# NUC029DE_v1 register map
File version: 1.0
Registers are 32-bit, read-write, reset 0x0 unless marked. A register's access mark holds for its fields unless they carry their own. Offsets are from the block's base; [hi:lo] are bit positions; {n}, {i} and the like mark numbered series; 'fields as' and 'values as' point back to an identical list.

## UART1 — UART Register Map
Base 0x40150000
0x00 UA_RBR ro reset not defined — UART Receive Buffer Register
  [7:0] RBR — Receive Buffer Register (Read Only). By reading this register, the UART will return the 8-bit data received from RX pin (LSB first).
0x00 UA_THR wo reset not defined (alternate view of UA_RBR) — UART Transmit Holding Register
  [7:0] THR — Transmit Holding Register. By writing one byte to this register, the data byte will be stored in transmitter FIFO. The UART Controller will send out the data stored in transmitter FIFO top location through the TX pin.
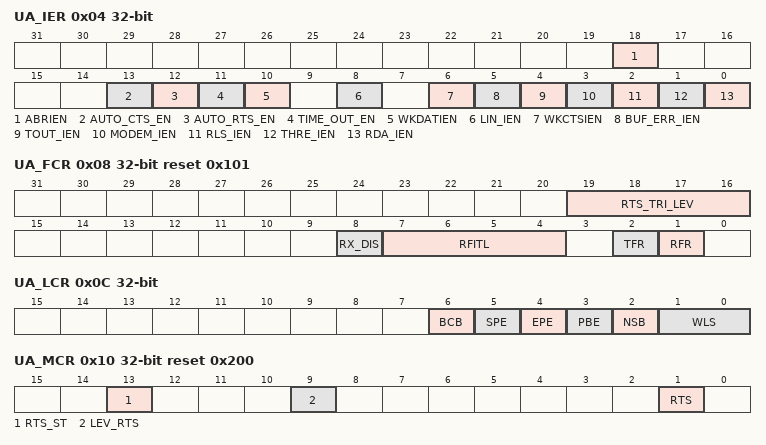
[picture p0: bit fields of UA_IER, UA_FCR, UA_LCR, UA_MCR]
0x04 UA_IER — UART Interrupt Enable Register
  [18] ABRIEN — Auto-Baud Rate Interrupt Enable Control
    0=Auto-baud rate interrupt Disabled; 1=Auto-baud rate interrupt Enabled
  [13] AUTO_CTS_EN — CTS Auto Flow Control Enable Coontrol (Available In UART0/UART1 Channel). When CTS auto-flow is enabled, the UART will send data to external device when CTS input assert (UART will not send data to device until CTS is asserted).
    0=CTS auto flow control Disabled; 1=CTS auto flow control Enabled
  [12] AUTO_RTS_EN — RTS Auto Flow Control Enable Coontrol ( Available In UART0/UART1 Channel). When RTS auto-flow is enabled, if the number of bytes in the RX FIFO equals the RTS_TRI_LEV (UA_FCR [19:16]), the UART will de-assert RTS signal.
    0=RTS auto flow control Disabled; 1=RTS auto flow control Enabled
  [11] TIME_OUT_EN — Time-Out Counter Enable Coontrol
    0=Time-out counter Disabled; 1=Time-out counter Enabled
  [10] WKDATIEN — Incoming Data Wake-Up Interrupt Enable Control. Note: Hardware will clear this bit when the incoming data wake-up operation finishes and "system clock" work stable.
    0=Incoming data wake-up system function Disabled; 1=Incoming data wake-up system function Enabled, when the system is in Power-down mode, incoming data will wake-up system from Power-down mode
  [8] LIN_IEN — LIN Bus Interrupt Enable Coontrol. Note: This field is used for LIN function mode.
    0=Lin bus interrupt Disabled; 1=Lin bus interrupt Enabled
  [6] WKCTSIEN — NCTS Wake-Up Interrupt Enable Control
    0=nCTS wake-up system function Disabled; 1=Wake-up system function Enabled, when the system is in Power-down mode, an external nCTS change will wake-up system from Power-down mode
  [5] BUF_ERR_IEN — Buffer Error Interrupt Enable Coontrol
    0=BUF_ERR_INT Masked off; 1=BUF_ERR_INT Enabled
  [4] TOUT_IEN — RX Time-Out Interrupt Enable Coontrol
    0=TOUT_INT Masked off; 1=TOUT_INT Enabled
  [3] MODEM_IEN — Modem Status Interrupt Enable Coontrol (Available In UART0/UART1 Channel)
    0=MODEM_INT Masked off; 1=MODEM_INT Enabled
  [2] RLS_IEN — Receive Line Status Interrupt Enable Coontrol
    0=RLS_INT Masked off; 1=RLS_INT Enabled
  [1] THRE_IEN — Transmit Holding Register Empty Interrupt Enable Coontrol
    0=THRE_INT Masked off; 1=THRE_INT Enabled
  [0] RDA_IEN — Receive Data Available Interrupt Enable Coontrol
    0=RDA_INT Masked off; 1=RDA_INT Enabled
0x08 UA_FCR reset 0x101 — UART FIFO Control Register
  [19:16] RTS_TRI_LEV — RTS Trigger Level For Auto-Flow Control Use (Available In UART0/UART1 Channel). Note: This field is used for RTS auto-flow control.
    0=RTS Trigger Level is 1 byte; 1=RTS Trigger Level is 4 bytes; 2=RTS Trigger Level is 8 bytes; 3=RTS Trigger Level is 14 bytes
  [8] RX_DIS — Receiver Disable Bit. The receiver is disabled or not (set 1 to disable receiver). Note: This field is used for RS-485 Normal Multi-drop mode. It should be programmed before RS-485_NMM (UA_ALT_CSR[8]) is programmed.
    0=Receiver Enabled; 1=Receiver Disabled
  [7:4] RFITL — RX FIFO Interrupt (INT_RDA) Trigger Level (Available In UART0/UART1/UART2 Channel). When the number of bytes in the receive FIFO equals the RFITL, the RDA_IF will be set (if UA_IER [RDA_IEN] enabled, and an interrupt will be generated).
    0=RX FIFO Interrupt Trigger Level is 1 byte. RX Buffer Interrupt Trigger Level is 1 byte; 1=RX FIFO Interrupt Trigger Level is 4 bytes; 2=RX FIFO Interrupt Trigger Level is 8 bytes; 3=RX FIFO Interrupt Trigger Level is 14 bytes
  [2] TFR — TX Field Software Reset. When TFR is set, all the byte in the transmit FIFO/ transmit buffer and TX internal state machine are cleared. Note: This bit will automatically clear at least 3 UART peripherial clock cycles.
    0=No effect; 1=Reset the TX internal state machine and pointers
  [1] RFR — RX Field Software Reset. When RFR is set, all the byte in the receiver FIFO /receive buffer and RX internal state machine are cleared. Note: This bit will automatically clear at least 3 UART peripherial clock cycles.
    0=No effect; 1=Reset the RX internal state machine and pointers
0x0C UA_LCR — UART Line Control Register
  [6] BCB — Break Control Bit. When this bit is set to logic 1, the serial data output (TX) is forced to the Spacing State (logic 0). This bit acts only on TX and has no effect on the transmitter logic.
  [5] SPE — Stick Parity Enable Coontrol
    0=Stick parity Disabled; 1=If PBE (UA_LCR[3]) and EBE (UA_LCR[4]) are logic 1, the parity bit is transmitted and checked as logic 0. If PBE (UA_LCR[3]) is 1 and EBE (UA_LCR[4]) is 0 then the parity bit is transmitted and checked as 1
  [4] EPE — Even Parity Enable Coontrol. This bit has effect only when PBE (UA_LCR[3]) is set.
    0=Odd number of logic 1's is transmitted and checked in each word; 1=Even number of logic 1's is transmitted and checked in each word
  [3] PBE — Parity Bit Enable Coontrol
    0=No parity bit; 1=Parity bit is generated on each outgoing character and is checked on each incoming data
  [2] NSB — Number Of "STOP Bit"
    0=One " STOP bit" is generated in the transmitted data; 1=When select 5-bit word length, 1.5 "STOP bit" is generated in the transmitted data. When select 6-,7- and 8-bti word length, 2 "STOP bit" is generated in the transmitted data
  [1:0] WLS — Word Length Selection
    {v}=Word length is {v+5}-bit (v=0..3)
0x10 UA_MCR reset 0x200 — UART Modem Control Register
  [13] RTS_ST ro — RTS Pin State (Read Only) ( Available In UART0/UART1 Channel). This bit mirror from RTS pin output of voltage logic status.
    0=RTS pin output is low level voltage logic state; 1=RTS pin output is high level voltage logic state
  [9] LEV_RTS — RTS Pin Active Level ( Available In UART0/UART1 Channel). This bit defines the active level state of RTS pin output. Note1: Refer to Figure 692 and Figure 693 for UART function mode. Note2: Refer to Figure 6103 and Figure 6104 for RS-485 function mode.
    0=RTS pin output is high level active; 1=RTS pin output is low level active
  [1] RTS — RTS (Request-To-Send) Signal Control (Available In UART0/UART1 Channel). This bit is direct control internal RTS signal active or not, and then drive the RTS pin output with LEV_RTS bit configuration. Note1: This RTS signal control bit is not effective when RTS auto-flow control is enabled in UART function mode. Note2: This RTS signal control bit is not effective when RS-485 auto direction mode (AUD) is enabled in RS-485 function mode.
    0=RTS signal is active; 1=RTS signal is inactive
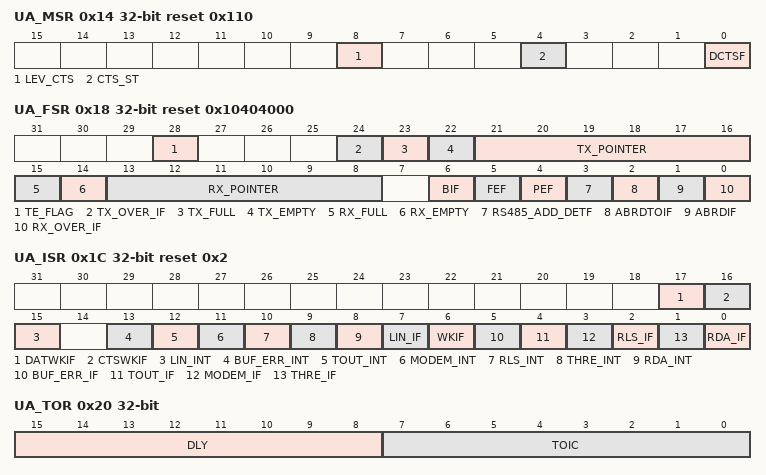
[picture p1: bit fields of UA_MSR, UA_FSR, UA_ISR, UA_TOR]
0x14 UA_MSR reset 0x110 — UART Modem Status Register
  [8] LEV_CTS — CTS Pin Active Level. This bit defines the active level state of CTS pin input. Note: Refer to Figure 691 for more information.
    0=CTS pin input is high level active; 1=CTS pin input is low level active
  [4] CTS_ST ro — CTS Pin Status (Read Only). This bit mirror from CTS pin input of voltage logic status. Note: This bit echoes when UART Controller peripheral clock is enabled, and CTS multi-function port is selected.
    0=CTS pin input is low level voltage logic state; 1=CTS pin input is high level voltage logic state
  [0] DCTSF ro — Detect CTS State Change Flag (Read Only). This bit is set whenever CTS input has change state, and it will generate Modem interrupt to CPU when MODEM_IEN (UA_IER [3]) is set to 1. Note: This bit is read only, but can be cleared by writing "1" to it.
    0=CTS input has not change state; 1=CTS input has change state
0x18 UA_FSR reset 0x10404000 — UART FIFO Status Register
  [28] TE_FLAG ro — Transmitter Empty Flag (Read Only). This bit is set by hardware when TX FIFO (UA_THR) is empty and the STOP bit of the last byte has been transmitted. (UART0/UART1/UART2). Note: This bit is cleared automatically when TX FIFO/TX Buffer is not empty or the last byte transmission has not completed.
    0=TX FIFO is not empty. TX Buffer is not empty; 1=TX FIFO is empty. TX Buffer is empty
  [24] TX_OVER_IF ro — TX Overflow Error Interrupt Flag (Read Only). If TX FIFO (UA_THR) is full, an additional write to UA_THR will cause this bit to logic 1. (UART0/UART1/UART2). Note: This bit is read only, but can be cleared by writing "1" to it.
    0=TX FIFO is not overflow. TX Buffer is not overflow; 1=TX FIFO is overflow. TX Buffer is overflow
  [23] TX_FULL ro — Transmitter FIFO Full (Read Only). This bit indicates TX FIFO is full or not. (UART0/UART1/UART2). This bit is set when the number of usage in TX Buffer is equal to 1 (UART3/UART4/UART5), otherwise is cleared by hardware.
    0=TX FIFO is not full. TX Buffer is not full; 1=TX FIFO is full. TX Buffer is full
  [22] TX_EMPTY ro — Transmitter FIFO Empty (Read Only). This bit indicates TX FIFO empty or not. (UART0/UART1/UART2). Note: When the last byte of TX Buffer has been transferred to Transmitter Shift Register, hardware sets this bit high. It will be cleared when writing data into THR (TX FIFO not empty).
    values as TE_FLAG
  [21:16] TX_POINTER ro — TX FIFO Pointer (Read Only). This field indicates the TX FIFO Buffer Pointer. When CPU writes one byte into UA_THR, then TX_POINTER increases one. When one byte of TX FIFO is transferred to Transmitter Shift Register, then TX_POINTER decreases one. The Maximum value shown in TX_POINTER is 15 (UART0/UART1/UART2). When the using level of TX FIFO Buffer is equal to 16, the TX_FULL bit is set to 1 and TX_POINTER will show 0. As one byte of TX FIFO is transferred to Transmitter Shift Register, the TX_FULL bit is cleared to 0 and TX_POINTER will show 15 (UART0/UART1/UART2). TX_POINTER is 0 (UART3/URT4/UART5). When TX Buffer is equal to 1, if one byte data is received, the TX_FULL bit is set to 1 and TX_POINTER will show 1. Once the TX Buffer is read, the TX_POINTER is 0.
  [15] RX_FULL ro — Receiver FIFO Full (Read Only). This bit initiates RX FIFO is full or not (UART0/UART1/UART2). Note: This bit is set when the number of usage in RX Buffer is equal to 1 (UART3/UART4/UART5), otherwise is cleared by hardware.
    0=RX FIFO is not full. RX buffer is not full; 1=RX FIFO is full. RX bufferis full
  [14] RX_EMPTY ro — Receiver FIFO Empty (Read Only). This bit initiate RX FIFO empty or not. (UART0/UART1/UART2). Note: When the last byte of RX Buffer has been read by CPU, hardware sets this bit high. It will be cleared when UART receives any new data.
    0=RX FIFO is not empty. RX Buffer is not empty; 1=RX FIFO is empty. RX Buffer is empty
  [13:8] RX_POINTER ro — RX FIFO Pointer (Read Only). This field indicates the RX FIFO Buffer Pointer. When UART receives one byte from external device, then RX_POINTER increases one. When one byte of RX FIFO is read by CPU, then RX_POINTER decreases one. The Maximum value shown in RX_POINTER is 15 (UART0/UART1/UART2). When the using level of RX FIFO Buffer equal to 16, the RX_FULL bit is set to 1 and RX_POINTER will show 0. As one byte of RX FIFO is read by CPU, the RX_FULL bit is cleared to 0 and RX_POINTER will show 15 (UART0/UART1/UART2). When RX Buffer is equal to 1, if one byte data is received, the RX_FULL bit is set to 1 and RX_POINTER will show 1. Once the RX Buffer is read, the RX_POINTER is 0.
  [6] BIF ro — Break Interrupt Flag (Read Only). This bit is set to logic 1 whenever the received data input(RX) is held in the "spacing state" (logic 0) for longer than a full word transmission time (that is, the total time of "start bit" + data bits + parity + stop bits) and is reset whenever the CPU writes 1 to this bit. Note: This bit is read only, but can be cleared by writing "1" to it.
    0=No Break interrupt is generated; 1=Break interrupt is generated
  [5] FEF ro — Framing Error Flag (Read Only). This bit is set to logic 1 whenever the received character does not have a valid "stop bit" (that is, the stop bit following the last data bit or parity bit is detected as logic 0), and is reset whenever the CPU writes 1 to this bit. Note: This bit is read only, but can be cleared by writing "1" to it.
    0=No framing error is generated; 1=Framing error is generated
  [4] PEF ro — Parity Error Flag (Read Only). This bit is set to logic 1 whenever the received character does not have a valid "parity bit", and is reset whenever the CPU writes 1 to this bit. Note: This bit is read only, but can be cleared by writing "1" to it.
    0=No parity error is generated; 1=Parity error is generated
  [3] RS485_ADD_DETF ro — RS-485 Address Byte Detection Flag (Read Only) (Available In UART0/UART1). Note1: This field is used for RS-485 function mode and RS485_ADD_EN (UA_ALT_CSR[15]) is set to 1 to enable Address detection mode. Note2: This bit is read only, but can be cleared by writing '1' to it.
    0=Receiver detects a data that is not an address bit (bit 9 ='1'); 1=Receiver detects a data that is an address bit (bit 9 ='1')
  [2] ABRDTOIF ro — Auto-Baud Rate Time-Out Interrupt (Read Only). Note1: This bit is set to logic "1" in Auto-baud Rate Detect mode and the baud rate counter is overflow. Note2: This bit is read only, but can be cleared by writing "1" to it.
    0=Auto-baud rate counter is underflow; 1=Auto-baud rate counter is overflow
  [1] ABRDIF ro — Auto-Baud Rate Detect Interrupt (Read Only). This bit is set to logic "1" when auto-baud rate detect function is finished. Note: This bit is read only, but can be cleared by writing "1" to it.
    0=Auto-baud rate detect function is not finished; 1=Auto-baud rate detect function is finished
  [0] RX_OVER_IF ro — RX Overflow Error IF (Read Only). This bit is set when RX FIFO overflow. If the number of bytes of received data is greater than RX_FIFO (UA_RBR) size, 16 bytes of UART0/UART1/UART2, this bit will be set. Note: This bit is read only, but can be cleared by writing "1" to it.
    0=RX FIFO is not overflow. RX Buffer is not overflow; 1=RX FIFO is overflow. RX Buffer is overflow
0x1C UA_ISR reset 0x2 — UART Interrupt Status Register
  [17] DATWKIF ro — Data Wake-Up Interrupt Flag (Read Only). This bit is set if chip wake-up from power-down state by data wake-up. Note1: If WKDATIEN (UA_IER[10]) is enabled, the wake-up interrupt is generated. Note2: This bit is read only, but can be cleared by writing '1' to it.
    0=Chip stays in power-down state; 1=Chip wake-up from power-down state by data wake-up
  [16] CTSWKIF ro — NCTS Wake-Up Interrupt Flag (Read Only). Note1: If WKCTSIEN (UA_IER[6])is enabled, the wake-up interrupt is generated. Note2: This bit is read only, but can be cleared by writing '1' to it.
    0=Chip stays in power-down state; 1=Chip wake-up from power-down state by nCTS wake-up
  [15] LIN_INT ro — LIN Bus Interrupt Indicator (Read Only). This bit is set if LIN_IEN (UA_IER[8]) and LIN _IF(UA_ISR[7]) are both set to 1.
    0=No LIN Bus interrupt is generated; 1=The LIN Bus interrupt is generated
  [13] BUF_ERR_INT ro — Buffer Error Interrupt Indicator (Read Only). This bit is set if BUF_ERR_IEN(UA_IER[5] and BUF_ERR_IF(UA_ISR[5]) are both set to 1.
    0=No buffer error interrupt is generated; 1=Buffer error interrupt is generated
  [12] TOUT_INT ro — Time-Out Interrupt Indicator (Read Only). This bit is set if TOUT_IEN(UA_IER[4]) and TOUT_IF(UA_ISR[4]) are both set to 1.
    0=No Tout interrupt is generated; 1=Tout interrupt is generated
  [11] MODEM_INT ro — MODEM Status Interrupt Indicator (Read Only) (Available In UART0/UART1 Channel). This bit is set if MODEM_IEN(UA_IER[3] and MODEM_IF(UA_ISR[4]) are both set to 1
    0=No Modem interrupt is generated; 1=Modem interrupt is generated
  [10] RLS_INT ro — Receive Line Status Interrupt Indicator (Read Only). This bit is set if RLS_IEN (UA_IER[2]) and RLS_IF(UA_ISR[2]) are both set to 1.
    0=No RLS interrupt is generated; 1=RLS interrupt is generated
  [9] THRE_INT ro — Transmit Holding Register Empty Interrupt Indicator (Read Only). This bit is set if THRE_IEN (UA_IER[1])and THRE_IF(UA_SR[1]) are both set to 1.
    0=No THRE interrupt is generated; 1=THRE interrupt is generated
  [8] RDA_INT ro — Receive Data Available Interrupt Indicator (Read Only). This bit is set if RDA_IEN (UA_IER[0]) and RDA_IF (UA_ISR[0]) are both set to 1.
    0=No RDA interrupt is generated; 1=RDA interrupt is generated
  [7] LIN_IF ro — LIN Bus Flag (Read Only)(UART0/UARt1/UART2). Note: This bit is read only. This bit is cleared when LINS_HDET_F (UA_LIN_SR[0]), LIN_BKDET_F (UA_LIN_SR[9]), BIT_ERR_F (UA_LIN_SR[9]), LINS_IDPENR_F (UA_LIN_SR[2]) and LINS_HERR_F (UA_LIN_SR[1]) all are cleared.
    0=None of LINS_HDET_F, LIN_BKDET_F, BIT_ERR_F, LINS_IDPERR_F and LINS_HERR_F is generated; 1=At least one of LINS_HDET_F, LIN_BKDET_F, BIT_ERR_F, LINS_IDPERR_F and LINS_HERR_F is generated
  [6] WKIF ro — UART Wake-Up Flag (Read Only). This bit is set when DATWKIF (UART_INTSTS[17]) or CTSWKIF(UART_INTSTS[16]) is set to 1. Note: This bit is read only. This bit is cleared if both of DATWKIF (UART_INTSTS[17]) and CTSWKIF (UART_INTSTS[16]) are cleared to 0 by writing 1 to DATWKIF (UART_INTSTS[17]) and CTSWKIF (UART_INTSTS[17]).
    0=No DATWKIF and CTSWKIF are generated; 1=DATWKIF or CTSWKIF
  [5] BUF_ERR_IF ro — Buffer Error Interrupt Flag (Read Only). This bit is set when the TX FIFO (UART0/UART1/UART2) / TX Buffer (UART3/UART4/UART5) or RX FIFO (UART0/UART1/UART2)/ RX Buffer (UART3/UART4/UART5) overflows (TX_OVER_IF (UA_FSR[24]) or RX_OVER_IF (UA_FSR[0]) is set). When BUF_ERR_IF (UA_ISR[5]) is set, the transfer is not correct. If BUF_ERR_IEN (UA_IER [8]) is enabled, the buffer error interrupt will be generated. Note: This bit is read only and reset to 0 when all bits of TX_OVER_IF(UA_FSR[24]) and RX_OVER_IF(UA_FSR[0]) are cleared.
    0=No buffer error interrupt flag is generated; 1=Buffer error interrupt flag is generated
  [4] TOUT_IF ro — Time-Out Interrupt Flag (Read Only). This bit is set when the RX FIFO (UART0/UART1/UART2) / RX Buffer (UART3/UART4/UART5) is not empty and no activities occurred in the RX FIFO and the time-out counter equal to TOIC. If TOUT_IEN (UA_IER [4]) is enabled, the Tout interrupt will be generated. Note: This bit is read only and user can read UA_RBR (RX is in active) to clear it.
    0=No Time-out interrupt flag is generated; 1=Time-out interrupt flag is generated
  [3] MODEM_IF ro — MODEM Interrupt Flag (Read Only) (Not Available In UART2 Channel). Note: This bit is read only and reset to 0 when bit DCTSF is cleared by a write 1 on DCTSF(UA_MSR[0]).
    0=No Modem interrupt flag is generated; 1=Modem interrupt flag is generated
  [2] RLS_IF ro — Receive Line Interrupt Flag (Read Only). This bit is set when the RX receive data have parity error, frame error or break error (at least one of 3 bits, BIF(UA_FSR[6]), FEF(UA_FSR[5]) and PEF(UA_FSR[4]), is set). If RLS_IEN (UA_IER [2]) is enabled, the RLS interrupt will be generated. Note2: This bit is read only and reset to 0 when all bits of BIF(UA_FSR[6]), FEF(UA_FSR[5]) and PEF(UA_FSR[4]) are cleared. Note3: In RS-485 function mode, this bit is read only and reset to 0 when all bits of BIF(UA_FSR[6]) , FEF(UA_FSR[5]) and PEF(UA_FSR[4]) and RS485_ADD_DETF (UA_FSR[3]) are cleared.
    0=No RLS interrupt flag is generated; 1=RLS interrupt flag is generated
  [1] THRE_IF ro — Transmit Holding Register Empty Interrupt Flag (Read Only). This bit is set when the last data of TX FIFO (UART0/UART1/UART2) / TX Buffer (UART3/UART4/UART5) is transferred to Transmitter Shift Register. If THRE_IEN (UA_IER[1]) is enabled, the THRE interrupt will be generated. Note: This bit is read only and it will be cleared when writing data into THR (TX FIFO not empty).
    0=No THRE interrupt flag is generated; 1=THRE interrupt flag is generated
  [0] RDA_IF ro — Receive Data Available Interrupt Flag (Read Only). When the number of bytes in the RX FIFO (UART0/UART1/UART2) / RX Buffer (UART3/UART4/UART5) equals the RFITL then the RDA_IF(UA_ISR[0]) will be set. If RDA_IEN (UA_IER [0]) is enabled, the RDA interrupt will be generated. Note: This bit is read only and it will be cleared when the number of unread bytes of RX FIFO drops below the threshold level (RFITL(UA_FCR[7:4]).
    0=No RDA interrupt flag is generated; 1=RDA interrupt flag is generated
0x20 UA_TOR — UART Time-out Register
  [15:8] DLY — TX Delay Time Value. This field is used to programming the transfer delay time between the last stop bit and next start bit.
  [7:0] TOIC — Time-Out Interrupt Comparator
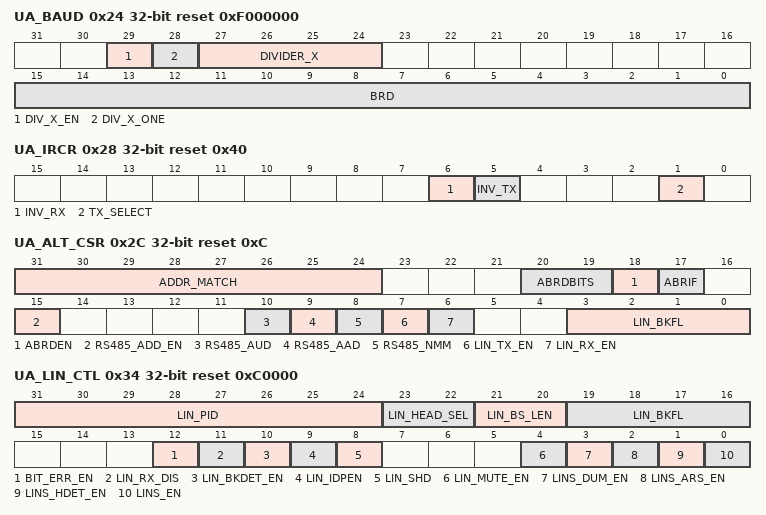
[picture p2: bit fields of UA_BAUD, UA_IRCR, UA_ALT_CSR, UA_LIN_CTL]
0x24 UA_BAUD reset 0xF000000 — UART Baud Rate Divisor Register
  [29] DIV_X_EN — Divider X Enable Coontrol. Refer to Table 624 UART Baud Rate Equation for more information. Note: In IrDA mode, this bit must disable.
    0=Divider X Disabled (the equation of M = 16); 1=Divider X Enabled (the equation of M = X+1, but DIVIDER_X [27:24] must = 8)
  [28] DIV_X_ONE — Divider X Equal To 1. Refer to Table 624 UART Baud Rate Equation for more information.
    0=Divider M = X (the equation of M = X+1, but DIVIDER_X[27:24] must = 8); 1=Divider M = 1 (the equation of M = 1, but BRD [15:0] must = 3)
  [27:24] DIVIDER_X
  [15:0] BRD — Baud Rate Divider. The field indicates the baud rate divider.
0x28 UA_IRCR reset 0x40 — UART IrDA Control Register
  [6] INV_RX — IrDA Inverse Receive Input Signal Control
    0=None inverse receiving input signal; 1=Inverse receiving input signal
  [5] INV_TX — IrDA Inverse Transmitting Output Signal Control
    0=None inverse transmitting signal; 1=Inverse transmitting output signal
  [1] TX_SELECT — IrDA Receiver/Transmitter Selection Enable Coontrol
    0=IrDA Transmitter Disabled and Receiver Enabled; 1=IrDA Transmitter Enabled and Receiver Disabled
0x2C UA_ALT_CSR reset 0xC — UART Alternate Control/Status Register
  [31:24] ADDR_MATCH — Address Match Value Register (Available In UART0/UART1). This field contains the RS-485 address match values. Note: This field is used for RS-485 auto address detection mode.
  [20:19] ABRDBITS — Auto-Baud Rate Detect Bit Length. Note: The calculation of bit number includes the START bit.
    0=1-bit time from Start bit to the 1st rising edge. The input pattern shall be 0x01; 1=2-bit time from Start bit to the 1st rising edge. The input pattern shall be 0x02; 2=4-bit time from Start bit to the 1st rising edge. The input pattern shall be 0x08; 3=8-bit time from Start bit to the 1st rising edge. The input pattern shall be 0x80
  [18] ABRDEN — Auto-Baud Rate Detect Enable Control. This bit is cleared automatically after auto-baud detection is finished.
    0=Auto-baud rate detect function Disabled; 1=Auto-baud rate detect function Enabled
  [17] ABRIF ro — Auto-Baud Rate Interrupt Flag (Read Only). This bit is set when auto-baud rate detection function finished or the auto-baud rate counter was overflow and if ABRIEN(UART_IEN [18]) is set then the auto-baud rate interrupt will be generated. Note: This bit is read only, but it can be cleared by writing "1" to ABRDTOIF (UA_FSR[2]) and ABRDIF(UA_FSR[1]).
  [15] RS485_ADD_EN — RS-485 Address Detection Enable Coontrol (Available In UART0/UART1). This bit is used to enable RS-485 Address Detection mode. Note: This bit is used for RS-485 any operation mode.
    0=Address detection mode Disabled; 1=Address detection mode Enabled
  [10] RS485_AUD — RS-485 Auto Direction Mode (AUD) (Available In UART0/UART1). Note: It can be active with RS-485_AAD or RS-485_NMM operation mode.
    0=RS-485 Auto Direction Operation mode (AUO) Disabled; 1=RS-485 Auto Direction Operation mode (AUO) Enabled
  [9] RS485_AAD — RS-485 Auto Address Detection Operation Mode (AAD) (Available In UART0/UART1). Note: It cannot be active with RS-485_NMM operation mode.
    0=RS-485 Auto Address Detection Operation mode (AAD) Disabled; 1=RS-485 Auto Address Detection Operation mode (AAD) Enabled
  [8] RS485_NMM — RS-485 Normal Multi-Drop Operation Mode (NMM) (Available In UART0/UART1). Note: It cannot be active with RS-485_AAD operation mode.
    0=RS-485 Normal Multi-drop Operation mode (NMM) Disabled; 1=RS-485 Normal Multi-drop Operation mode (NMM) Enabled
  [7] LIN_TX_EN — LIN TX Break Mode Enable Coontrol (Available In UART0/UART1/UART2). Note: When TX break field transfer operation finished, this bit will be cleared automatically.
    0=LIN TX Break mode Disabled; 1=LIN TX Break mode Enabled
  [6] LIN_RX_EN — LIN RX Enable Coontrol (Available In UART0/UART1/UART2)
    0=LIN RX mode Disabled; 1=LIN RX mode Enabled
  [3:0] LIN_BKFL — UART LIN Break Field Length (Available In UART0/UART1/UART2). This field indicates a 4-bit LIN TX break field count. Note1: This break field length is LIN_BKFL + 1.
0x30 UA_FUN_SEL — UART Function Select Register
  [1:0] FUN_SEL — Function Select Enable Coontrol
    0=UART function Enabled; 1=LIN function Enabled. (Available in UART0/UART1/UART2); 2=IrDA function Enabled; 3=RS-485 function Enabled. (Available in UART0/UART1)
0x34 UA_LIN_CTL reset 0xC0000 — UART LIN Control Register
  [31:24] LIN_PID — LIN PID Register. If the parity generated by hardware, user fill ID0~ID5, (LIN_PID [29:24] )hardware will calculate P0 (LIN_PID[30]) and P1 (LIN_PID[31]), otherwise user must filled frame ID and parity in this field. . Note1: User can fill any 8-bit value to this field and the bit 24 indicates ID0 (LSB first). Note2: This field can be used for LIN master mode or slave mode.
  [23:22] LIN_HEAD_SEL — LIN Header Select
    0=The LIN header includes "break field"; 1=The LIN header includes "break field" and "sync field"; 2=The LIN header includes "break field", "sync field" and "frame ID field"
  [21:20] LIN_BS_LEN — LIN Break/Sync Delimiter Length . Note: This bit used for LIN master to sending header field.
    0=The LIN break/sync delimiter length is 1 bit time; 2=The LIN break/sync delimiter length is 2 bit time. The LIN break/sync delimiter length is 3 bit time; 3=The LIN break/sync delimiter length is 4 bit time
  [19:16] LIN_BKFL — LIN Break Field Length. This field indicates a 4-bit LIN TX break field count. Note1: These registers are shadow registers of LIN_BKFL, User can read/write it by setting LIN_BKFL (UA_ALT_CSR[3:0]) or LIN_BKFL (UA_LIN_CTL[19:16]. Note2: This break field length is LIN_BKFL + 1.
  [12] BIT_ERR_EN — Bit Error Detect Enable Coontrol
    0=Bit error detection function Disabled; 1=Bit error detection Enabled
  [11] LIN_RX_DIS — LIN Receiver Disable Bit
    0=LIN receiver Enabled; 1=LIN receiver Disabled
  [10] LIN_BKDET_EN — LIN Break Detection Enable Coontrol
    0=LIN break detection Disabled; 1=LIN break detection Enabled
  [9] LIN_IDPEN — LIN ID Parity Enable Coontrol
    0=LIN frame ID parity Disabled; 1=LIN frame ID parity Enabled
  [8] LIN_SHD — LIN TX Send Header Enable Coontrol. The LIN TX header can be "break field" or "break and sync field" or "break, sync and frame ID field", it is depend on setting LIN_HEAD_SEL (UA_LIN_CTL[23:22]). Note1: These registers are shadow registers of LIN_SHD (UA_ALT_CSR [7]); user can read/write it by setting LIN_SHD (UA_ALT_CSR [7]) or LIN_SHD (UA_LIN_CTL [8]). Note2: When transmitter header field (it may be "break" or "break + sync" or "break + sync + frame ID" selected by LIN_HEAD_SEL (UA_LIN_CTL[23:22]) field) transfer operation finished, this bit will be cleared automatically.
    0=Send LIN TX header Disabled; 1=Send LIN TX header Enabled
  [4] LIN_MUTE_EN — LIN Mute Mode Enable Coontrol. Note: The exit from mute mode condition and each control and interactions of this field are explained in (LIN slave mode).
    0=LIN mute mode Disabled; 1=LIN mute mode Enabled
  [3] LINS_DUM_EN — LIN Slave Divider Update Method Enable Coontrol. Note2: This bit used for LIN Slave Automatic Resynchronization mode. (for Non-Automatic Resynchronization mode, this bit should be kept cleared). Note3: The control and interactions of this field are explained in section 6.11.5.8.4. (Slave mode with automatic resynchronization).
    0=UA_BAUD updated is written by software (if no automatic resynchronization update occurs at the same time); 1=UA_BAUD is updated at the next received character. User must set the bit before checksum reception
  [2] LINS_ARS_EN — LIN Slave Automatic Resynchronization Mode Enable Coontrol. Note2: When operation in Automatic Resynchronization mode, the baud rate setting must be mode2 (BAUD_M1 (UA_BAUD [29]) and BAUD_M0 (UA_BAUD [28]) must be 1). Note3: The control and interactions of this field are explained in section 6.11.5.8.4. (Slave mode with automatic resynchronization).
    0=LIN automatic resynchronization Disabled; 1=LIN automatic resynchronization Enabled
  [1] LINS_HDET_EN — LIN Slave Header Detection Enable Coontrol
    0=LIN slave header detection Disabled; 1=LIN slave header detection Enabled
  [0] LINS_EN — LIN Slave Mode Enable Coontrol
    0=LIN slave mode Disabled; 1=LIN slave mode Enabled
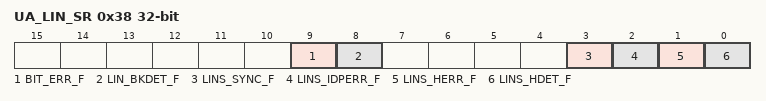
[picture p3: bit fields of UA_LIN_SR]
0x38 UA_LIN_SR — UART LIN Status Register
  [9] BIT_ERR_F ro — Bit Error Detect Status Flag (Read Only). At TX transfer state, hardware will monitoring the bus state, if the input pin (SIN) state not equals to the output pin (SOUT) state, BIT_ERR_F (UA_LIN_SR[9]) will be set.
  [8] LIN_BKDET_F ro — LIN Break Detection Flag (Read Only). This bit is set by hardware when a break is detected and be cleared by writing 1 to it through software.
    0=LIN break not detected; 1=LIN break detected
  [3] LINS_SYNC_F — LIN Slave Sync Field. This bit indicates that the LIN sync field is being analyzed in Automatic Resynchronization mode. When the receiver header have some error been detect, user must reset the internal circuit to re-search new frame header by writing 1 to this bit. Note2: This bit is read only, but it can be cleared by writing 1 to it. Note3: When writing 1 to it, hardware will reload the initial baud rate and re-search a new frame header.
    0=The current character is not at LIN sync state; 1=The current character is at LIN sync state
  [2] LINS_IDPERR_F ro — LIN Slave ID Parity Error Flag (Read Only). This bit is set by hardware when receipted frame ID parity is not correct.
    0=No active; 1=Receipted frame ID parity is not correct
  [1] LINS_HERR_F ro — LIN Slave Header Error Flag (Read Only). This bit is set by hardware when a LIN header error is detected in LIN slave mode and be cleared by writing 1 to it. The header errors include "break delimiter is too short (less than 0.5 bit time)", "frame error in sync field or Identifier field", "sync field data is not 0x55 in Non-Automatic Resynchronization mode", "sync field deviation error with Automatic Resynchronization mode", "sync field measure time-out with Automatic Resynchronization mode" and "LIN header reception time-out".
    0=LIN header error not detected; 1=LIN header error detected
  [0] LINS_HDET_F ro — LIN Slave Header Detection Flag (Read Only). This bit is set by hardware when a LIN header is detected in LIN slave mode and be cleared by writing 1 to it. Note3: When enable ID parity check LIN_IDPEN (UA_LIN_CTL [9]), if hardware detect complete header ("break + sync + frame ID"), the LINS_HEDT_F will be set whether the frame ID correct or not.
    0=LIN header not detected; 1=LIN header detected (break + sync + frame ID)
